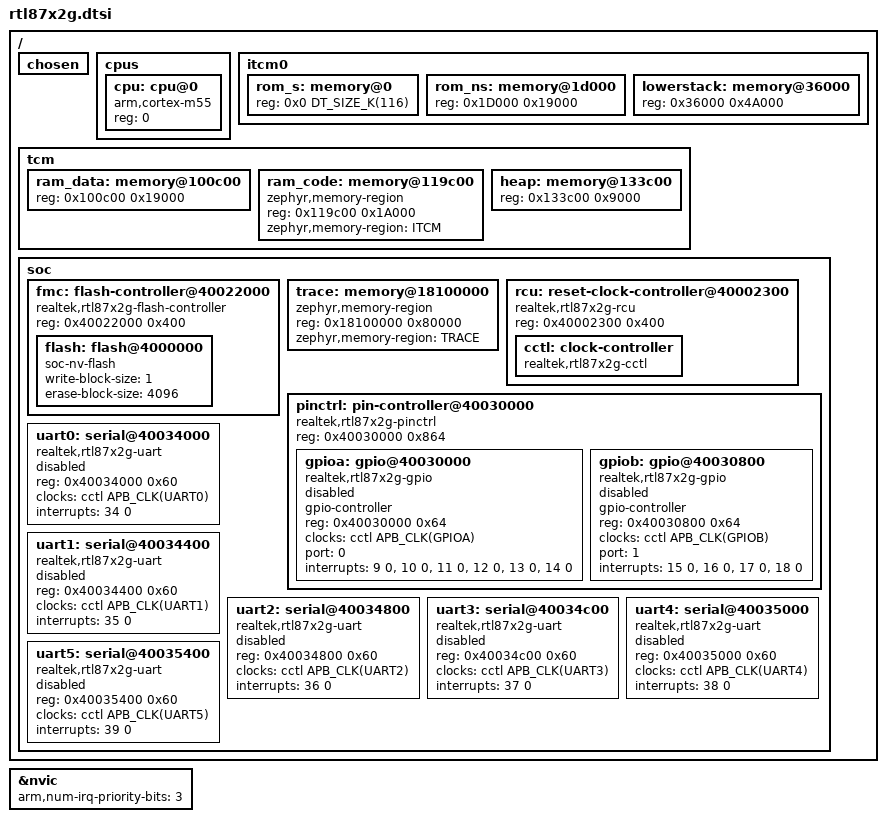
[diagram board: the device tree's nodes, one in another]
#include <mem.h>
#include <arm/armv8.1-m.dtsi>
#include <freq.h>
#include <dt-bindings/pinctrl/rtl87x2g-pinctrl.h>
#include <dt-bindings/clock/rtl87x2g-clocks.h>
#include <zephyr/dt-bindings/gpio/gpio.h>

/ {
	chosen {
	};

	cpus {
		#address-cells = <1>;
		#size-cells = <0>;

		cpu: cpu@0 {
			device_type = "cpu";
			compatible = "arm,cortex-m55";
			reg = <0>;
			#address-cells = <1>;
			#size-cells = <1>;
		};
	};

	itcm0 {
		#address-cells = <1>;
		#size-cells = <1>;

		rom_s: memory@0 {
			device_type = "secure rom code region";
			reg = <0x0 DT_SIZE_K(116)>;
		};
		rom_ns: memory@1d000 {
			device_type = "non-secure rom code region";
			reg = <0x1D000 0x19000>;
		};
		lowerstack: memory@36000 {
			device_type = "lowerstack code region";
			reg = <0x36000 0x4A000>;
		};
	};

	tcm {
		#address-cells = <1>;
		#size-cells = <1>;

		ram_data: memory@100c00 {
			device_type = "ram data region";
			reg = <0x100c00 0x19000>;
		};
		ram_code: memory@119c00 {
			device_type = "ram code region";
			compatible = "zephyr,memory-region", "arm,itcm";
			reg = <0x119c00 0x1A000>;
			zephyr,memory-region = "ITCM";
		};
		heap: memory@133c00 {
			device_type = "heap region";
			reg = <0x133c00 0x9000>;
		};
	};

	soc {
		fmc: flash-controller@40022000 {
			compatible = "realtek,rtl87x2g-flash-controller";
			reg = <0x40022000 0x400>;
			#address-cells = <1>;
			#size-cells = <1>;
			status = "okay";

			flash: flash@4000000 {
				compatible = "soc-nv-flash";
				write-block-size = <1>;
				erase-block-size = <4096>;
			};
		};

		trace: memory@18100000 {
			compatible = "zephyr,memory-region";
			reg = <0x18100000 0x80000>;
			zephyr,memory-region = "TRACE";
		};

		rcu: reset-clock-controller@40002300 {
			compatible = "realtek,rtl87x2g-rcu";
			reg = <0x40002300 0x400>;
			status = "okay";

			cctl: clock-controller {
				compatible = "realtek,rtl87x2g-cctl";
				#clock-cells = <1>;
				status = "okay";
			};
		};

		pinctrl: pin-controller@40030000 {
			compatible = "realtek,rtl87x2g-pinctrl";
			#address-cells = <1>;
			#size-cells = <1>;
			reg = <0x40030000 0x864>;

			gpioa: gpio@40030000 {
				compatible = "realtek,rtl87x2g-gpio";
				gpio-controller;
				#gpio-cells = <2>;
				reg = <0x40030000 0x64>;
				clocks = <&cctl APB_CLK(GPIOA)>;
				port = <0>;
				interrupts = <9 0>, <10 0>, <11 0>, <12 0>, <13 0>, <14 0>;
				status = "disabled";
			};

			gpiob: gpio@40030800 {
				compatible = "realtek,rtl87x2g-gpio";
				gpio-controller;
				#gpio-cells = <2>;
				reg = <0x40030800 0x64>;
				clocks = <&cctl APB_CLK(GPIOB)>;
				port = <1>;
				interrupts = <15 0>, <16 0>, <17 0>, <18 0>;
				status = "disabled";
			};
		};

		uart0: serial@40034000 {
			compatible = "realtek,rtl87x2g-uart";
			reg = <0x40034000 0x60>;
			clocks = <&cctl APB_CLK(UART0)>;
			interrupts = <34 0>;
			status = "disabled";
		};

		uart1: serial@40034400 {
			compatible = "realtek,rtl87x2g-uart";
			reg = <0x40034400 0x60>;
			clocks = <&cctl APB_CLK(UART1)>;
			interrupts = <35 0>;
			status = "disabled";
		};

		uart2: serial@40034800 {
			compatible = "realtek,rtl87x2g-uart";
			reg = <0x40034800 0x60>;
			clocks = <&cctl APB_CLK(UART2)>;
			interrupts = <36 0>;
			status = "disabled";
		};

		uart3: serial@40034c00 {
			compatible = "realtek,rtl87x2g-uart";
			reg = <0x40034c00 0x60>;
			clocks = <&cctl APB_CLK(UART3)>;
			interrupts = <37 0>;
			status = "disabled";
		};

		uart4: serial@40035000 {
			compatible = "realtek,rtl87x2g-uart";
			reg = <0x40035000 0x60>;
			clocks = <&cctl APB_CLK(UART4)>;
			interrupts = <38 0>;
			status = "disabled";
		};

		uart5: serial@40035400 {
			compatible = "realtek,rtl87x2g-uart";
			reg = <0x40035400 0x60>;
			clocks = <&cctl APB_CLK(UART5)>;
			interrupts = <39 0>;
			status = "disabled";
		};
	};

};

&nvic {
	arm,num-irq-priority-bits = <3>;
};
